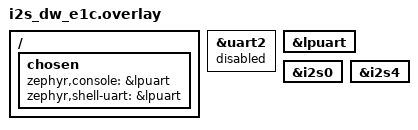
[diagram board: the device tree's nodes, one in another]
/* Copyright (C) 2026 Alif Semiconductor - All Rights Reserved.
 * Use, distribution and modification of this code is permitted under the
 * terms stated in the Alif Semiconductor Software License Agreement
 *
 * You should have received a copy of the Alif Semiconductor Software
 * License Agreement with this file. If not, please write to:
 * contact@alifsemi.com, or visit: https://alifsemi.com/license
 *
 */

/*
 * E1C HE: I2S0 speaker (TX) + I2S4 LPI2S mic (RX).
 * PM: TCM boot S2RAM (E1C/B1 memory masks).
 * Console: lpuart (overrides uart2 set by pm_tcm_common.overlay).
 */

#include "pm_tcm_e1c_b1.overlay"

/ {
	chosen {
		zephyr,console    = &lpuart;
		zephyr,shell-uart = &lpuart;
	};
};

&uart2 {
	status = "disabled";
};

&lpuart {
	status = "okay";
};

i2s_tx: &i2s0 {
	status = "okay";
};

i2s_rx: &i2s4 {
	status = "okay";
};
